VERSION ""

NS_ :

BS_:

BU_: 718

BO_ 134 Steering: 8 718
  SG_ LWI_Steering_angle : 16|13@1+ (0.1,0) [0|800] "Unit_DegreOfArc" 718
  SG_ LWI_Steering_Speed : 31|9@1+ (5,0) [0|2500] "Unit_DegreOfArcPerSecon" 718
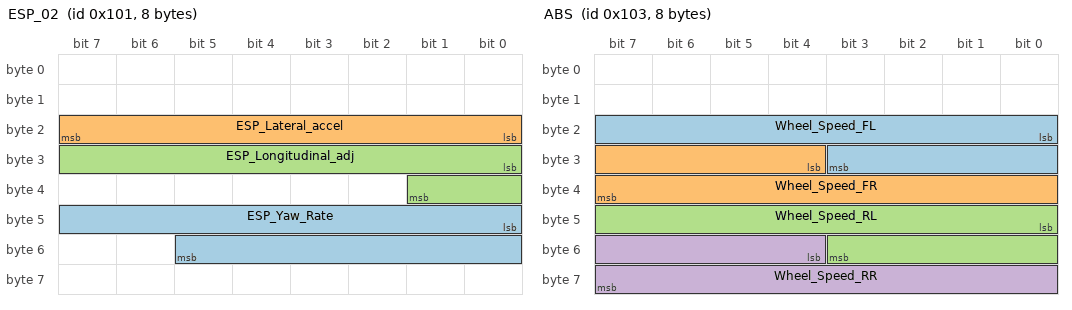
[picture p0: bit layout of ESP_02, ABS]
BO_ 257 ESP_02: 8 718
  SG_ ESP_Yaw_Rate : 40|14@1+ (0.01,0) [0|163.82] "Unit_DegreOfArcPerSecon" 718
  SG_ ESP_Lateral_accel : 16|8@1+ (0.01,-1.27) [-1.27|1.27] "Unit_ForceOfGravi" 718
  SG_ ESP_Longitudinal_adj : 24|10@1+ (0.03125,-16) [-16|15.90625] "Unit_MeterPerSeconSquar" 718

BO_ 259 ABS: 8 718
  SG_ Wheel_Speed_FL : 16|12@1+ (0.103,0) [0|325.12] "Unit_KiloMeterPerHou" 718
  SG_ Wheel_Speed_FR : 28|12@1+ (0.103,0) [0|325.12] "Unit_KiloMeterPerHou" 718
  SG_ Wheel_Speed_RL : 40|12@1+ (0.103,0) [0|325.12] "Unit_KiloMeterPerHou" 718
  SG_ Wheel_Speed_RR : 52|12@1+ (0.103,0) [0|325.12] "Unit_KiloMeterPerHou" 718

BO_ 260 Transmission: 8 718
  SG_ EPB_Clutch_Pedal : 32|8@1+ (0.4,-10) [8|92] "Unit_PerCent" 718

BO_ 261 Throttle: 8 718
  SG_ Throttle_Position : 48|8@1+ (0.4,0) [0|1] "Unit_PerCent" 718
  SG_ Throttle_RPM : 16|16@1+ (0.25,0) [0|10000] "RPM" 718

BO_ 262 Brakes: 8 718
  SG_ Brake_PressureSig352 : 16|10@1+ (0.3,-30) [-30|276.6] "Unit_Bar" 718
  SG_ Brake_Light : 26|1@1+ (1,1) [0|1] "On Off" 718

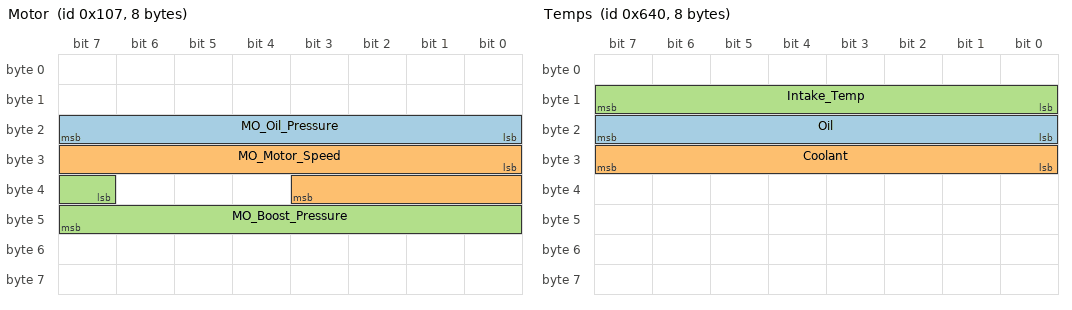
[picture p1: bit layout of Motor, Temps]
BO_ 263 Motor: 8 718
  SG_ MO_Oil_Pressure : 16|8@1+ (0.04,0) [0|10] "Unit_Bar" 718
  SG_ MO_Motor_Speed : 24|12@1+ (3,0) [0|12282] "Unit_MinutInver" 718
  SG_ MO_Boost_Pressure : 39|9@1+ (0.01,0) [0|5.1] "Unit_Bar" 718

BO_ 779 Speed: 8 718
  SG_ KBI_displayed_speed : 48|10@1+ (0.32,0) [0|325.12] "Unit_KiloMeterPerHour" 718

BO_ 1600 Temps: 8 718
  SG_ Oil : 16|8@1+ (1,-60) [0|1] "Degrees C" 718
  SG_ Coolant : 24|8@1+ (1,-75) [0|1] "Degrees C" 718
  SG_ Intake_Temp : 8|8@1+ (0.75,-48) [-48|141.75] "Unit_DegreCelsi" 718

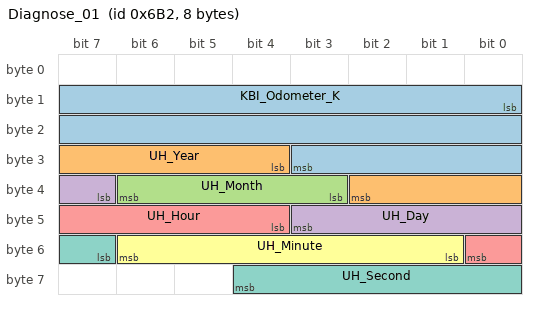
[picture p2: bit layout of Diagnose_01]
BO_ 1714 Diagnose_01: 8 718
  SG_ KBI_Odometer_K : 8|20@1+ (1,0) [0|1048573] "Unit_KiloMeter" 718
  SG_ UH_Year : 28|7@1+ (1,2000) [2000|2127] "Unit_Year" 718
  SG_ UH_Month : 35|4@1+ (1,0) [1|12] "Unit_Month" 718
  SG_ UH_Day : 39|5@1+ (1,0) [1|31] "Unit_Day" 718
  SG_ UH_Hour : 44|5@1+ (1,0) [0|23] "Unit_Hours" 718
  SG_ UH_Minute : 49|6@1+ (1,0) [0|59] "Unit_Minut" 718
  SG_ UH_Second : 55|6@1+ (1,0) [0|59] "Unit_Secon" 718

BO_ 1719 Fuel: 8 718
  SG_ KBI_Contents_Tank : 40|7@1+ (1,0) [0|125] "Unit_Liter" 718
  SG_ KBI_Outside_Temp : 56|8@1+ (0.5,-50) [-50|75] "Unit_DegreCelsi" 718
